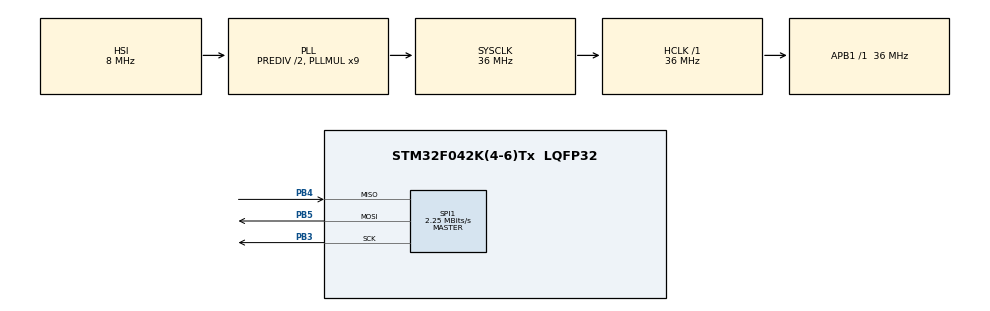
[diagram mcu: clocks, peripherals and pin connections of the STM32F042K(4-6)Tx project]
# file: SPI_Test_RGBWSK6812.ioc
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Mcu.Family=STM32F0
Mcu.Name=STM32F042K(4-6)Tx
Mcu.Package=LQFP32
PA13.Mode=Serial_Wire
PA13.Signal=SYS_SWDIO
PA14.Mode=Serial_Wire
PA14.Signal=SYS_SWCLK
PB3.Mode=Full_Duplex_Master
PB3.Signal=SPI1_SCK
PB4.Mode=Full_Duplex_Master
PB4.Signal=SPI1_MISO
PB5.Mode=Full_Duplex_Master
PB5.Signal=SPI1_MOSI
ProjectManager.HeapSize=0x200
ProjectManager.StackSize=0x400
ProjectManager.TargetToolchain=STM32CubeIDE
RCC.AHBFreq_Value=36000000
RCC.APB1Freq_Value=36000000
RCC.APB1TimFreq_Value=36000000
RCC.HCLKFreq_Value=36000000
RCC.PLLDivider=RCC_PREDIV_DIV2
RCC.PLLMUL=RCC_PLL_MUL9
RCC.SYSCLKFreq_VALUE=36000000
RCC.SYSCLKSource=RCC_SYSCLKSOURCE_PLLCLK
SPI1.BaudRatePrescaler=SPI_BAUDRATEPRESCALER_16
SPI1.CLKPhase=SPI_PHASE_2EDGE
SPI1.CLKPolarity=SPI_POLARITY_HIGH
SPI1.CalculateBaudRate=2.25 MBits/s
SPI1.DataSize=SPI_DATASIZE_8BIT
SPI1.Direction=SPI_DIRECTION_2LINES
SPI1.Mode=SPI_MODE_MASTER
SPI1.VirtualType=VM_MASTER
board=custom

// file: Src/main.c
/* USER CODE BEGIN Header */
/**
  ******************************************************************************
  * @file           : main.c
  * @brief          : Main program body
  ******************************************************************************
  * @attention
  *
  * <h2><center>&copy; Copyright (c) 2020 STMicroelectronics.
  * All rights reserved.</center></h2>
  *
  * This software component is licensed by ST under Ultimate Liberty license
  * SLA0044, the "License"; You may not use this file except in compliance with
  * the License. You may obtain a copy of the License at:
  *                             www.st.com/SLA0044
  *
  ******************************************************************************
  */
/* USER CODE END Header */

#include "main.h"

/* USER CODE BEGIN Includes */
#include "smartled.h"
/* USER CODE END Includes */

SPI_HandleTypeDef hspi1;

void SystemClock_Config(void);
static void MX_GPIO_Init(void);
static void MX_SPI1_Init(void);

int main(void)
{

  /* MCU Configuration--------------------------------------------------------*/

  /* Reset of all peripherals, Initializes the Flash interface and the Systick. */
  HAL_Init();

  /* Configure the system clock */
  SystemClock_Config();

  /* Initialize all configured peripherals */
  MX_GPIO_Init();
  MX_SPI1_Init();
  /* USER CODE BEGIN 2 */
  smartled_init(&hspi1);
  /* USER CODE END 2 */

  /* Infinite loop */
  while (1)
  {

    /* USER CODE BEGIN 3 */

	  for(uint8_t i = 0; i < 72; i++) {
		  smartled_set(i, 50, 50, 50);
		  smartled_set(maxleds-i,50,50,50);
		  smartled_write();
		  HAL_Delay(20);
	  }

	  smartled_set_all(0,0,0);

	  for(uint8_t i = 0; i < 72; i++) {
		  smartled_set(i, 100-i, 0, 30+i);
		  if(i > 0) {
			  smartled_set(i-1, 0, 0,0);
			  smartled_set(maxleds-i, 100-i, 0, 30+i);
			  smartled_set(maxleds-i+1, 0, 0, 0);
		  }
		  else {
			  smartled_set(maxleds, 100-i, 0, 30+i);
		  }

		  smartled_write();
		  HAL_Delay(20);
	  }

	  smartled_set_all(0,0,0);
	  smartled_write();

	  for(uint8_t i = 0; i < 72; i++) {
		  smartled_set(i, 100-i, 0, 30+i);
		  if(i > 0) {
			  smartled_set(i-1, 0, 0,0);
			  smartled_set(maxleds-i, 100-i, 0, 30+i);
			  smartled_set(maxleds-i+1, 0, 0, 0);
		  }
		  else {
			  smartled_set(maxleds, 100-i, 0, 30+i);
		  }

		  smartled_write();
		  HAL_Delay(5);
	  }

	  for(uint8_t i = 0; i < 72; i++) {
		  smartled_set(i, 100-i, 0, 30+i);
		  if(i > 0) {
			  smartled_set(maxleds-i, 100-i, 0, 30+i);
		  }
		  else {
			  smartled_set(maxleds, 100-i, 0, 30+i);
		  }

		  smartled_write();
		  HAL_Delay(20);
	  }

  }
  /* USER CODE END 3 */
}

void SystemClock_Config(void)
{
  RCC_OscInitTypeDef RCC_OscInitStruct = {0};
  RCC_ClkInitTypeDef RCC_ClkInitStruct = {0};

  /** Initializes the CPU, AHB and APB busses clocks
  */
  RCC_OscInitStruct.OscillatorType = RCC_OSCILLATORTYPE_HSI;
  RCC_OscInitStruct.HSIState = RCC_HSI_ON;
  RCC_OscInitStruct.HSICalibrationValue = RCC_HSICALIBRATION_DEFAULT;
  RCC_OscInitStruct.PLL.PLLState = RCC_PLL_ON;
  RCC_OscInitStruct.PLL.PLLSource = RCC_PLLSOURCE_HSI;
  RCC_OscInitStruct.PLL.PLLMUL = RCC_PLL_MUL9;
  RCC_OscInitStruct.PLL.PREDIV = RCC_PREDIV_DIV2;
  if (HAL_RCC_OscConfig(&RCC_OscInitStruct) != HAL_OK)
  {
    Error_Handler();
  }
  /** Initializes the CPU, AHB and APB busses clocks
  */
  RCC_ClkInitStruct.ClockType = RCC_CLOCKTYPE_HCLK|RCC_CLOCKTYPE_SYSCLK
                              |RCC_CLOCKTYPE_PCLK1;
  RCC_ClkInitStruct.SYSCLKSource = RCC_SYSCLKSOURCE_PLLCLK;
  RCC_ClkInitStruct.AHBCLKDivider = RCC_SYSCLK_DIV1;
  RCC_ClkInitStruct.APB1CLKDivider = RCC_HCLK_DIV1;

  if (HAL_RCC_ClockConfig(&RCC_ClkInitStruct, FLASH_LATENCY_1) != HAL_OK)
  {
    Error_Handler();
  }
}

static void MX_SPI1_Init(void)
{

  /* SPI1 parameter configuration*/
  hspi1.Instance = SPI1;
  hspi1.Init.Mode = SPI_MODE_MASTER;
  hspi1.Init.Direction = SPI_DIRECTION_2LINES;
  hspi1.Init.DataSize = SPI_DATASIZE_8BIT;
  hspi1.Init.CLKPolarity = SPI_POLARITY_HIGH;
  hspi1.Init.CLKPhase = SPI_PHASE_2EDGE;
  hspi1.Init.NSS = SPI_NSS_SOFT;
  hspi1.Init.BaudRatePrescaler = SPI_BAUDRATEPRESCALER_16;
  hspi1.Init.FirstBit = SPI_FIRSTBIT_MSB;
  hspi1.Init.TIMode = SPI_TIMODE_DISABLE;
  hspi1.Init.CRCCalculation = SPI_CRCCALCULATION_DISABLE;
  hspi1.Init.CRCPolynomial = 7;
  hspi1.Init.CRCLength = SPI_CRC_LENGTH_DATASIZE;
  hspi1.Init.NSSPMode = SPI_NSS_PULSE_DISABLE;
  if (HAL_SPI_Init(&hspi1) != HAL_OK)
  {
    Error_Handler();
  }

}

static void MX_GPIO_Init(void)
{

  /* GPIO Ports Clock Enable */
  __HAL_RCC_GPIOA_CLK_ENABLE();
  __HAL_RCC_GPIOB_CLK_ENABLE();

}

void Error_Handler(void)
{
}

/************************ (C) COPYRIGHT STMicroelectronics *****END OF FILE****/
